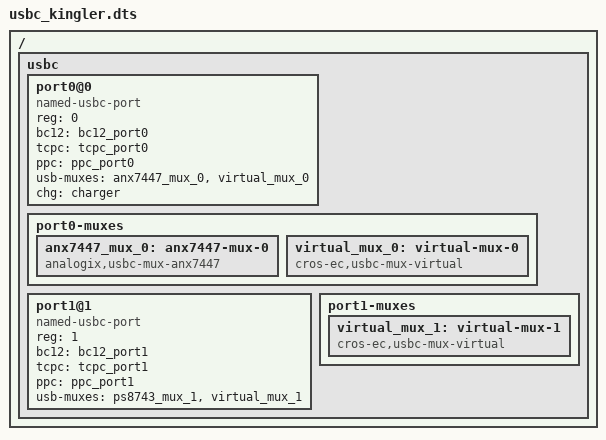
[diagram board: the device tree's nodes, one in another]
/* Copyright 2021 The ChromiumOS Authors
 * Use of this source code is governed by a BSD-style license that can be
 * found in the LICENSE file.
 */

/ {
	usbc {
		#address-cells = <1>;
		#size-cells = <0>;

		port0@0 {
			compatible = "named-usbc-port";
			reg = <0>;
			bc12 = <&bc12_port0>;
			tcpc = <&tcpc_port0>;
			ppc = <&ppc_port0>;
			usb-muxes = <&anx7447_mux_0 &virtual_mux_0>;
			chg = <&charger>;
		};

		port0-muxes {
			anx7447_mux_0: anx7447-mux-0 {
				compatible = "analogix,usbc-mux-anx7447";
			};
			virtual_mux_0: virtual-mux-0 {
				compatible = "cros-ec,usbc-mux-virtual";
			};
		};

		port1@1 {
			compatible = "named-usbc-port";
			reg = <1>;
			bc12 = <&bc12_port1>;
			tcpc = <&tcpc_port1>;
			ppc = <&ppc_port1>;
			usb-muxes = <&ps8743_mux_1 &virtual_mux_1>;
		};

		port1-muxes {
			virtual_mux_1: virtual-mux-1 {
				compatible = "cros-ec,usbc-mux-virtual";
			};
		};
	};
};
